# STM32H7R3xx register map
File version: 1.0
Registers are 32-bit, read-write, reset 0x0 unless marked. A register's access mark holds for its fields unless they carry their own. Offsets are from the block's base; [hi:lo] are bit positions.

## RSSLIB_PFUNC — RSSLib callable function pointer structure
Base 0x1FF1FD4C
0x00 SetSecOB ro
0x14 GetRssStatus ro
0x18 SetProductState ro
0x1C DataProvisioning ro
0x20 JumpHDPLvl2 ro
0x24 JumpHDPLvl3 ro
0x28 GetProductState ro

## WWDG — Window Watchdog
Base 0x40002C00
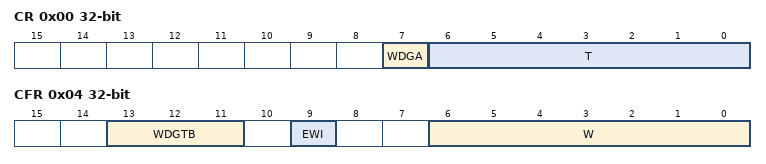
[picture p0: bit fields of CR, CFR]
0x00 CR — WWDG Control register
  [7] WDGA — Activation bit
  [6:0] T — T[6:0] bits (7-Bit counter (MSB to LSB))
0x04 CFR — WWDG Configuration register
  [13:11] WDGTB — WDGTB[2:0] bits (Timer Base)
    0=PRESCALER_1 (WWDG counter clock = (PCLK1/4096)/1); 1=PRESCALER_2 (WWDG counter clock = (PCLK1/4096)/2); 2=PRESCALER_4 (WWDG counter clock = (PCLK1/4096)/4); 3=PRESCALER_8 (WWDG counter clock = (PCLK1/4096)/8); 4=PRESCALER_16 (WWDG counter clock = (PCLK1/4096)/16); 5=PRESCALER_32 (WWDG counter clock = (PCLK1/4096)/32); 6=PRESCALER_64 (WWDG counter clock = (PCLK1/4096)/64); 7=PRESCALER_128 (WWDG counter clock = (PCLK1/4096)/128)
  [9] EWI — Early Wakeup Interrupt
  [6:0] W — W[6:0] bits (7-bit window value)
0x08 SR — WWDG Status register
  [0] EWIF — Early Wakeup Interrupt Flag

## SPDIFRX — SPDIF-RX Interface
Base 0x40004000
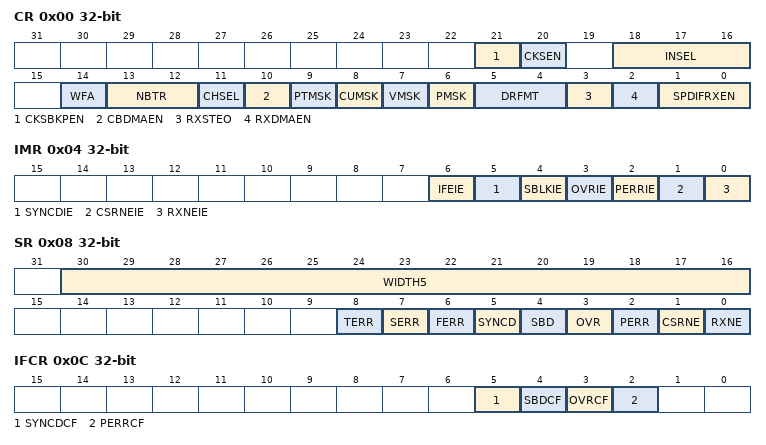
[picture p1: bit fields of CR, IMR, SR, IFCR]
0x00 CR — Control register
  [21] CKSBKPEN — Backup Symbol Clock Enable
  [20] CKSEN — Symbol Clock Enable
  [18:16] INSEL — SPDIF input selection
  [14] WFA — Wait For Activity
  [13:12] NBTR — Maximum allowed re-tries during synchronization phase
  [11] CHSEL — Channel Selection
  [10] CBDMAEN — Control Buffer DMA ENable for control flow
  [9] PTMSK — Mask of Preamble Type bits
  [8] CUMSK — Mask of channel status and user bits
  [7] VMSK — Mask of Validity bit
  [6] PMSK — Mask Parity error bit
  [5:4] DRFMT — RX Data format
  [3] RXSTEO — Stereo Mode
  [2] RXDMAEN — Receiver DMA Enable for data flow
  [1:0] SPDIFRXEN — Peripheral Block Enable
0x04 IMR — Interrupt mask register
  [6] IFEIE — Serial Interface Error Interrupt Enable
  [5] SYNCDIE — Synchronization Done
  [4] SBLKIE — Synchronization Block Detected Interrupt Enable
  [3] OVRIE — Overrun error Interrupt Enable
  [2] PERRIE — Parity error interrupt enable
  [1] CSRNEIE — Control Buffer Ready Interrupt Enable
  [0] RXNEIE — RXNE interrupt enable
0x08 SR — Status register
  [30:16] WIDTH5 — Duration of 5 symbols counted with spdif_clk
  [8] TERR — Time-out error
  [7] SERR — Synchronization error
  [6] FERR — Framing error
  [5] SYNCD — Synchronization Done
  [4] SBD — Synchronization Block Detected
  [3] OVR — Overrun error
  [2] PERR — Parity error
  [1] CSRNE — The Control Buffer register is not empty
  [0] RXNE — Read data register not empty
0x0C IFCR — Interrupt Flag Clear register
  [5] SYNCDCF — Clears the Synchronization Done flag
  [4] SBDCF — Clears the Synchronization Block Detected flag
  [3] OVRCF — Clears the Overrun error flag
  [2] PERRCF — Clears the Parity error flag
0x10 DR — Data input register
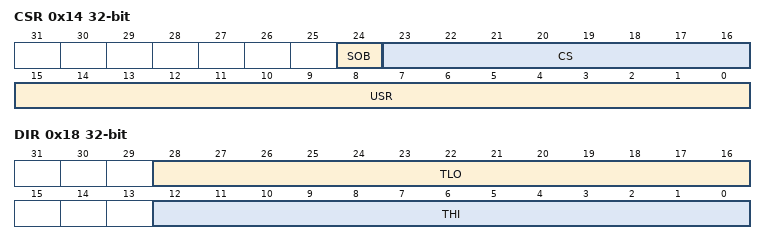
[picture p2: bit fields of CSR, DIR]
0x14 CSR — Channel Status register
  [24] SOB — Start Of Block
  [23:16] CS — Channel A status information
  [15:0] USR — User data information
0x18 DIR — Debug Information register
  [28:16] TLO — Threshold HIGH
  [12:0] THI — Threshold LOW

## CEC — Consumer Electronics Control
Base 0x40006C00
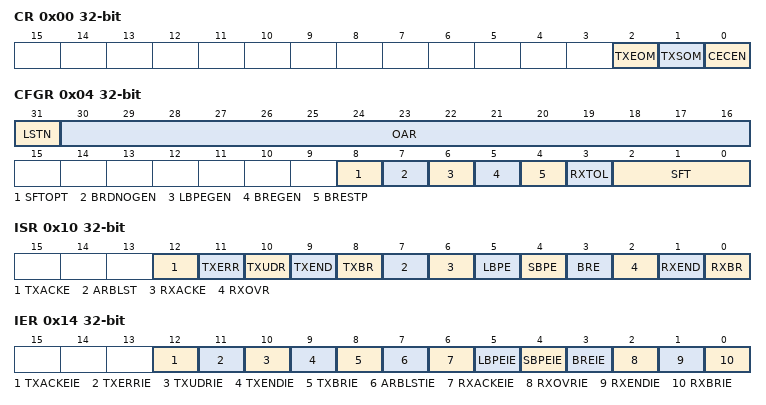
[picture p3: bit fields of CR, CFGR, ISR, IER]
0x00 CR — CEC control register
  [2] TXEOM — CEC Tx End Of Message
  [1] TXSOM — CEC Tx Start Of Message
  [0] CECEN — CEC Enable
0x04 CFGR — CEC configuration register
  [31] LSTN — CEC Listen mode
  [30:16] OAR — CEC Own Address
  [8] SFTOPT — CEC Signal Free Time optional
  [7] BRDNOGEN — CEC Broadcast No error generation
  [6] LBPEGEN — CEC Long Bit Period Error generation
  [5] BREGEN — CEC Bit Rising Error generation
  [4] BRESTP — CEC Rx Stop
  [3] RXTOL — CEC Tolerance
  [2:0] SFT — CEC Signal Free Time
0x08 TXDR — CEC Tx data register
  [7:0] TXD — CEC Tx Data
0x0C RXDR — CEC Rx Data Register
  [7:0] RXD — CEC Rx Data
0x10 ISR — CEC Interrupt and Status Register
  [12] TXACKE — CEC Tx Missing Acknowledge
  [11] TXERR — CEC Tx-Error
  [10] TXUDR — CEC Tx-Buffer Underrun
  [9] TXEND — CEC End of Transmission
  [8] TXBR — CEC Tx Byte Request
  [7] ARBLST — CEC Arbitration Lost
  [6] RXACKE — CEC Rx Missing Acknowledge
  [5] LBPE — CEC Rx Long Bit period Error
  [4] SBPE — CEC Rx Short Bit period Error
  [3] BRE — CEC Rx Bit Rising Error
  [2] RXOVR — CEC Rx-Overrun
  [1] RXEND — CEC End Of Reception
  [0] RXBR — CEC Rx-Byte Received
0x14 IER — CEC interrupt enable register
  [12] TXACKEIE — CEC Tx Missing Acknowledge IT Enable
  [11] TXERRIE — CEC Tx-Error IT Enable
  [10] TXUDRIE — CEC Tx-Buffer Underrun IT Enable
  [9] TXENDIE — CEC End of Transmission IT Enable
  [8] TXBRIE — CEC Tx Byte Request IT Enable
  [7] ARBLSTIE — CEC Arbitration Lost IT Enable
  [6] RXACKEIE — CEC Rx Missing Acknowledge IT Enable
  [5] LBPEIE — CEC Rx Long Bit period Error IT Enable
  [4] SBPEIE — CEC Rx Short Bit period Error IT Enable
  [3] BREIE — CEC Rx Bit Rising Error IT Enable
  [2] RXOVRIE — CEC Rx-Overrun IT Enable
  [1] RXENDIE — CEC End Of Reception IT Enable
  [0] RXBRIE — CEC Rx-Byte Received IT Enable
